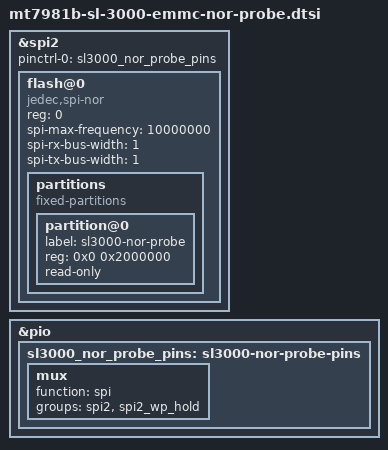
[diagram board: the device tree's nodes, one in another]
// SPDX-License-Identifier: GPL-2.0-or-later OR MIT
// SPI2 wiring from OpenWrt PR 24172, head 08de1f5c5a47776641a3eb8d96bd76e402c5ee63.
// Expose the whole NOR read-only; do not assume or consume its factory layout yet.
&spi2 {
	pinctrl-names = "default";
	pinctrl-0 = <&sl3000_nor_probe_pins>;
	status = "okay";

	flash@0 {
		compatible = "jedec,spi-nor";
		reg = <0>;
		spi-max-frequency = <10000000>;
		spi-rx-bus-width = <1>;
		spi-tx-bus-width = <1>;

		partitions {
			compatible = "fixed-partitions";
			#address-cells = <1>;
			#size-cells = <1>;

			partition@0 {
				label = "sl3000-nor-probe";
				reg = <0x0 0x2000000>;
				read-only;
			};
		};
	};
};

&pio {
	sl3000_nor_probe_pins: sl3000-nor-probe-pins {
		mux {
			function = "spi";
			groups = "spi2", "spi2_wp_hold";
		};
	};
};
